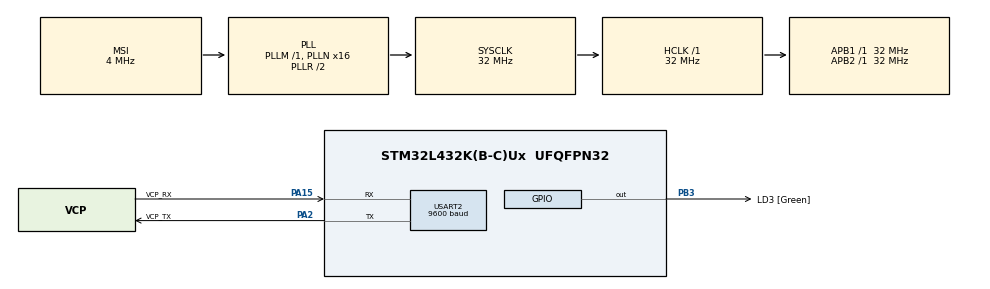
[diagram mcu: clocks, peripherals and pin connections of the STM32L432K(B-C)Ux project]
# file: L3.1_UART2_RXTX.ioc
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Dma.Request0=USART2_RX
Dma.Request1=USART2_TX
Dma.USART2_RX.0.Direction=DMA_PERIPH_TO_MEMORY
Dma.USART2_RX.0.Instance=DMA1_Channel6
Dma.USART2_RX.0.MemDataAlignment=DMA_MDATAALIGN_BYTE
Dma.USART2_RX.0.MemInc=DMA_MINC_ENABLE
Dma.USART2_RX.0.Mode=DMA_NORMAL
Dma.USART2_RX.0.PeriphDataAlignment=DMA_PDATAALIGN_BYTE
Dma.USART2_RX.0.PeriphInc=DMA_PINC_DISABLE
Dma.USART2_RX.0.Priority=DMA_PRIORITY_LOW
Dma.USART2_TX.1.Direction=DMA_MEMORY_TO_PERIPH
Dma.USART2_TX.1.Instance=DMA1_Channel7
Dma.USART2_TX.1.MemDataAlignment=DMA_MDATAALIGN_BYTE
Dma.USART2_TX.1.MemInc=DMA_MINC_ENABLE
Dma.USART2_TX.1.Mode=DMA_NORMAL
Dma.USART2_TX.1.PeriphDataAlignment=DMA_PDATAALIGN_BYTE
Dma.USART2_TX.1.PeriphInc=DMA_PINC_DISABLE
Dma.USART2_TX.1.Priority=DMA_PRIORITY_LOW
Mcu.Family=STM32L4
Mcu.Name=STM32L432K(B-C)Ux
Mcu.Package=UFQFPN32
NVIC.DMA1_Channel6_IRQn=true\:0\:0\:false\:false\:true\:false\:true\:true
NVIC.DMA1_Channel7_IRQn=true\:0\:0\:false\:false\:true\:false\:true\:true
NVIC.PriorityGroup=NVIC_PRIORITYGROUP_4
NVIC.USART2_IRQn=true\:0\:0\:false\:false\:true\:true\:true\:true
PA0.GPIO_Label=MCO [High speed clock in]
PA0.Mode=HSE-External-Clock-Source-for-LittleOrca
PA0.Signal=RCC_CK_IN
PA13\ (JTMS-SWDIO).GPIO_Label=SWDIO
PA13\ (JTMS-SWDIO).Mode=Serial_Wire
PA13\ (JTMS-SWDIO).Signal=SYS_JTMS-SWDIO
PA14\ (JTCK-SWCLK).GPIO_Label=SWCLK
PA14\ (JTCK-SWCLK).Mode=Serial_Wire
PA14\ (JTCK-SWCLK).Signal=SYS_JTCK-SWCLK
PA15\ (JTDI).GPIO_Label=VCP_RX
PA15\ (JTDI).Mode=Asynchronous
PA15\ (JTDI).Signal=USART2_RX
PA2.GPIO_Label=VCP_TX
PA2.Mode=Asynchronous
PA2.Signal=USART2_TX
PB3\ (JTDO-TRACESWO).GPIO_Label=LD3 [Green]
PB3\ (JTDO-TRACESWO).Signal=GPIO_Output
PC14-OSC32_IN\ (PC14).Mode=LSE-External-Oscillator
PC14-OSC32_IN\ (PC14).Signal=RCC_OSC32_IN
PC15-OSC32_OUT\ (PC15).Mode=LSE-External-Oscillator
PC15-OSC32_OUT\ (PC15).Signal=RCC_OSC32_OUT
ProjectManager.HeapSize=0x200
ProjectManager.StackSize=0x400
ProjectManager.TargetToolchain=STM32CubeIDE
RCC.AHBFreq_Value=32000000
RCC.APB1Freq_Value=32000000
RCC.APB1TimFreq_Value=32000000
RCC.APB2Freq_Value=32000000
RCC.APB2TimFreq_Value=32000000
RCC.CortexFreq_Value=32000000
RCC.HCLKFreq_Value=32000000
RCC.HSE_VALUE=8000000
RCC.HSI16_VALUE=16000000
RCC.HSI48_VALUE=48000000
RCC.HSI_VALUE=16000000
RCC.MSI_VALUE=4000000
RCC.PLLMUL=RCC_PLLMUL_4
RCC.PLLN=16
RCC.SYSCLKFreq_VALUE=32000000
RCC.SYSCLKSource=RCC_SYSCLKSOURCE_PLLCLK
RCC.VCOOutputFreq_Value=64000000
USART2.BaudRate=9600
USART2.VirtualMode-Asynchronous=VM_ASYNC
board=NUCLEO-L432KC

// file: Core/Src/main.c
/* USER CODE BEGIN Header */
/**
  ******************************************************************************
  * @file           : main.c
  * @brief          : Main program body
  ******************************************************************************
  * @attention
  *
  * Copyright (c) 2024 STMicroelectronics.
  * All rights reserved.
  *
  * This software is licensed under terms that can be found in the LICENSE file
  * in the root directory of this software component.
  * If no LICENSE file comes with this software, it is provided AS-IS.
  *
  ******************************************************************************
  */

/*
 * ChatGPT:	- HAL_UART_ErrorCallback vs HAL_DMA_ErrorCallback
 *			- stm32 L4 HAL_UART_ErrorCallback error handling logic
 *
 *
 * Structure of HAL_DMA_ErrorCallback
 *
 * Identify the DMA Instance:
 * 		Use the hdma parameter to determine which DMA channel experienced the error.
 *
 * Log the Error:
 * 		Use a logging mechanism (e.g., printing to console, sending an error message,
 * 		etc.) to capture the error context.
 *
 * Clear the Error:
 * 		If applicable, you might want to clear the error flags associated with the DMA.
 *
 * Abort the DMA Transfer:
 * 		Call HAL_DMA_Abort() to stop the DMA transfer and clean up any resources.
 *
 * Optionally, Reinitialize the DMA:
 * 		Depending on the application, you might need to reconfigure or restart the DMA
 * 		after handling the error.
 *
 * Notify Other System Components:
 * 		If other parts of your system need to be aware of the error (e.g., an application layer),
 * 		send a notification or update a status variable.
 */

/*
 * Breakdown of Key Components
 *
 * Error Callback Function:
 * 		This function is called automatically when a UART error occurs. Ensure it's configured
 * 		properly in your UART initialization.
 *
 * dentify UART Instance:
 * 		The code checks if the error relates to UART2. This is crucial for applications with multiple UARTs.
 *
 * DMA Abort Handling:
 * 		Abort the DMA: Call HAL_DMA_Abort() to stop the ongoing DMA transfer. Check the return value
 * 		to ensure the abort was successful.
 *
 * 		Clear Error Flags: Use __HAL_DMA_CLEAR_FLAG() to clear relevant error flags, such as transfer
 * 		errors, FIFO errors, and direct memory errors.
 *
 * Stop UART DMA:
 * 		Use HAL_UART_DMAStop() to stop any ongoing DMA operations related to the UART. This prevents
 * 		further erroneous transmissions.
 *
 * Optional Reinitialization:
 * 		If necessary, you can reinitialize the UART peripheral by uncommenting the HAL_UART_Init() line.
 * 		This step may be required depending on your application's state management.
 *
 * Notify Other Components:
 * 		Consider implementing a mechanism to notify other parts of your application about the error, such
 * 		as setting an error state or invoking an error handler function.
 */

/* USER CODE END Header */
#include "main.h"

/* USER CODE BEGIN Includes */
#include "stdio.h"
#include "string.h"
/* USER CODE END Includes */

UART_HandleTypeDef huart2;
DMA_HandleTypeDef hdma_usart2_rx;
DMA_HandleTypeDef hdma_usart2_tx;

/* USER CODE BEGIN PV */
uint8_t dataBufferTx[] = "Hello, UART with DMA!\r\n";		//data buffer tx
/* USER CODE END PV */

void SystemClock_Config(void);
static void MX_GPIO_Init(void);
static void MX_DMA_Init(void);
static void MX_USART2_UART_Init(void);

/* USER CODE BEGIN 0 */

/*
 * Error Code description UART1
 * 0xA0....UART1 Unknown Error
 * 0xA1....UART1 Overrun Error
 * 0xA2....UART1 Noise Error
 * 0xA3....UART1 Framing Error
 * 0xA4....UART1 Parity Error
 */

/*
 * Error Code description UART2
 * 0xB0....UART2 Unknown Error
 * 0xB1....UART2 Overrun Error
 * 0xB2....UART2 Noise Error
 * 0xB3....UART2 Framing Error
 * 0xB4....UART2 Parity Error
 */

void LogError(uint8_t errorCode)
{
	char message[50];

    // Implement your logging mechanism, e.g., send to UART, store in buffer

	// Example: send error code to a debug UART
    sprintf(message, "UART Error: 0x%08X\n", errorCode);
    HAL_UART_Transmit(&huart2, (uint8_t*)message, strlen(message), HAL_MAX_DELAY);
}

void resetUART(UART_HandleTypeDef *huart)
{
	if (huart == NULL || huart->Instance != USART1 || huart->Instance != USART2)
	{
		return; // Error: Invalid handle
	}

	if (huart->Instance == USART1)
		{
			// Disable the UART2 peripheral
			__HAL_UART_DISABLE(huart);

			// Clear the RX buffer
			while (__HAL_UART_GET_FLAG(huart, UART_FLAG_RXNE))
			{
				(void)huart->Instance->RDR; // Read the data register to clear RXNE
			}

			// Reset the UART2 peripheral
			__HAL_RCC_USART1_FORCE_RESET();
			__HAL_RCC_USART1_RELEASE_RESET();

			// Reinitialize the UART2 peripheral
			if (HAL_UART_Init(huart) == HAL_OK)		// Init UART1
			{
				// Reinitialize successful
			}else
			{
				// Reinitialize not successful
			}
		}

	if (huart->Instance == USART2)
	{
		// Disable the UART2 peripheral
		__HAL_UART_DISABLE(huart);

		// Clear the RX buffer
		while (__HAL_UART_GET_FLAG(huart, UART_FLAG_RXNE))
		{
			(void)huart->Instance->RDR; // Read the data register to clear RXNE
		}

		// Reset the UART2 peripheral
		__HAL_RCC_USART2_FORCE_RESET();
		__HAL_RCC_USART2_RELEASE_RESET();

		// Reinitialize the UART2 peripheral
		if (HAL_UART_Init(huart) == HAL_OK)		// Init UART2
		{
			// Reinitialize successful
		}else
		{
			// Reinitialize not successful
		}
	}
}

//void Error_Handler(void)
//{
//	// User can add their own implementation to report the HAL error return state
//    while (1)
//    {
//    	// Optionally toggle an LED or send an error message
//        HAL_Delay(100);
//        // Example: Toggle an LED connected to a GPIO pin
//        HAL_GPIO_TogglePin(LD3_GPIO_Port, LD3_Pin); // Adjust pin according to your setup
//    }
//}

//------------------------------Error Handling Functions UART1 and UART2------------------------------
// Handle overrun error
void HandleOverrunErrorUART(UART_HandleTypeDef *huart)
{
	if (huart->Instance == USART2)		// log the error
	{
		LogError(0xA1);
	}else if (huart->Instance == USART2)
	{
		LogError(0xB1);
	}

	__HAL_UART_CLEAR_OREFLAG(huart);	// clear error flag
	resetUART(huart);					// reset UART
}

// Handle noise error
void HandleNoiseErrorUART(UART_HandleTypeDef *huart)
{
	if (huart->Instance == USART2)		// log the error
	{
		LogError(0xA2);
	}else if (huart->Instance == USART2)
	{
		LogError(0xB2);
	}

	__HAL_UART_CLEAR_NEFLAG(huart);		// clear error flag
}

// Handle framing error
void HandleFramingErrorUART(UART_HandleTypeDef *huart)
{
	if (huart->Instance == USART2)		// log the error
	{
		LogError(0xA3);
	}else if (huart->Instance == USART2)
	{
		LogError(0xB3);
	}

	__HAL_UART_CLEAR_FEFLAG(huart);		// clear error flag
}

// Handle parity error
void HandleParityErrorUART(UART_HandleTypeDef *huart)
{
	if (huart->Instance == USART2)		// log the error
	{
		LogError(0xA4);
	}else if (huart->Instance == USART2)
	{
		LogError(0xB4);
	}

	__HAL_UART_CLEAR_PEFLAG(huart);		// clear error flag
}

// Handle unknown errors
void HandleUnknownErrorUART(UART_HandleTypeDef *huart)
{
	if (huart->Instance == USART2)		// log the error
	{
		LogError(0xA0);
	}else if (huart->Instance == USART2)
	{
		LogError(0xB0);
	}

	//resetUART();						// reset UART2
}

void HAL_UART_ErrorCallback(UART_HandleTypeDef *huart)
{
	if (huart == NULL || huart->Instance != USART1 || huart->Instance != USART2)
	{
		return; // Error: Invalid handle
	}

    //Error Handling UART1 and UART2

	switch (huart->ErrorCode)
	{
		case HAL_UART_ERROR_ORE:
			// Handle overrun error
			HandleOverrunErrorUART(huart);
			break;
		case HAL_UART_ERROR_NE:
			// Handle noise error
			HandleNoiseErrorUART(huart);
			break;
		case HAL_UART_ERROR_FE:
			// Handle framing error
			HandleFramingErrorUART(huart);
			break;
		case HAL_UART_ERROR_PE:
			// Handle parity error
			HandleParityErrorUART(huart);
			break;
		default:
			// Handle unknown errors
			HandleUnknownErrorUART(huart);
			break;
	}
}

// Callback for DMA transmission complete
//void HAL_DMA_ErrorCallback(DMA_HandleTypeDef *hdma)
//{
//    // Step 1: Identify the DMA instance
//    if (hdma->Instance == DMA1_Channel6)		//UART2, TX
//    {
//        // Step 2: Log the error for DMA1_Channel6
//        //printf("Error occurred on DMA1_Channel6.\n");
//
//        // Step 3: Clear any error flags
//        __HAL_DMA_CLEAR_FLAG(hdma, DMA_FLAG_TE6);
//    }
//    else if (hdma->Instance == DMA1_Channel7)	//UART2, RX
//    {
//        // Step 2: Log the error for DMA1_Channel7
//    	//printf("Error occurred on DMA1_Channel7.\n");
//
//        // Step 3: Clear any error flags
//        __HAL_DMA_CLEAR_FLAG(hdma, DMA_FLAG_TE7);
//    }
//    // Add additional channels as needed
//
//    // Step 4: Abort the DMA transfer
//    if (HAL_DMA_Abort(hdma) != HAL_OK)
//    {
//        // Handle abort error if necessary
//    	//printf("Failed to abort DMA transfer.\n");
//    }
//
//    // Step 5: Optional - Reinitialize the DMA if needed
//    // HAL_DMA_Init(hdma); // Uncomment if you wish to reinitialize
//
//    // Step 6: Notify other parts of the application if needed
//    // e.g., set an error flag, send a message, etc.
//}

/* USER CODE END 0 */

int main(void)
{

  /* MCU Configuration--------------------------------------------------------*/

  /* Reset of all peripherals, Initializes the Flash interface and the Systick. */
  HAL_Init();

  /* Configure the system clock */
  SystemClock_Config();

  /* Initialize all configured peripherals */
  MX_GPIO_Init();
  MX_DMA_Init();
  MX_USART2_UART_Init();

  /* Infinite loop */
  /* USER CODE BEGIN WHILE */
  while (1)
  {
	  HAL_Delay(1000);

	  if (HAL_UART_Transmit_DMA(&huart2, dataBufferTx, sizeof(dataBufferTx)) != HAL_OK)
	  {
		  // Transmission error handling
		  Error_Handler();
	  }

    /* USER CODE END WHILE */

  }
}

void SystemClock_Config(void)
{
  RCC_OscInitTypeDef RCC_OscInitStruct = {0};
  RCC_ClkInitTypeDef RCC_ClkInitStruct = {0};

  /** Configure the main internal regulator output voltage
  */
  if (HAL_PWREx_ControlVoltageScaling(PWR_REGULATOR_VOLTAGE_SCALE1) != HAL_OK)
  {
    Error_Handler();
  }

  /** Configure LSE Drive Capability
  */
  HAL_PWR_EnableBkUpAccess();
  __HAL_RCC_LSEDRIVE_CONFIG(RCC_LSEDRIVE_LOW);

  /** Initializes the RCC Oscillators according to the specified parameters
  * in the RCC_OscInitTypeDef structure.
  */
  RCC_OscInitStruct.OscillatorType = RCC_OSCILLATORTYPE_LSE|RCC_OSCILLATORTYPE_MSI;
  RCC_OscInitStruct.LSEState = RCC_LSE_ON;
  RCC_OscInitStruct.MSIState = RCC_MSI_ON;
  RCC_OscInitStruct.MSICalibrationValue = 0;
  RCC_OscInitStruct.MSIClockRange = RCC_MSIRANGE_6;
  RCC_OscInitStruct.PLL.PLLState = RCC_PLL_ON;
  RCC_OscInitStruct.PLL.PLLSource = RCC_PLLSOURCE_MSI;
  RCC_OscInitStruct.PLL.PLLM = 1;
  RCC_OscInitStruct.PLL.PLLN = 16;
  RCC_OscInitStruct.PLL.PLLP = RCC_PLLP_DIV7;
  RCC_OscInitStruct.PLL.PLLQ = RCC_PLLQ_DIV2;
  RCC_OscInitStruct.PLL.PLLR = RCC_PLLR_DIV2;
  if (HAL_RCC_OscConfig(&RCC_OscInitStruct) != HAL_OK)
  {
    Error_Handler();
  }

  /** Initializes the CPU, AHB and APB buses clocks
  */
  RCC_ClkInitStruct.ClockType = RCC_CLOCKTYPE_HCLK|RCC_CLOCKTYPE_SYSCLK
                              |RCC_CLOCKTYPE_PCLK1|RCC_CLOCKTYPE_PCLK2;
  RCC_ClkInitStruct.SYSCLKSource = RCC_SYSCLKSOURCE_PLLCLK;
  RCC_ClkInitStruct.AHBCLKDivider = RCC_SYSCLK_DIV1;
  RCC_ClkInitStruct.APB1CLKDivider = RCC_HCLK_DIV1;
  RCC_ClkInitStruct.APB2CLKDivider = RCC_HCLK_DIV1;

  if (HAL_RCC_ClockConfig(&RCC_ClkInitStruct, FLASH_LATENCY_1) != HAL_OK)
  {
    Error_Handler();
  }

  /** Enable MSI Auto calibration
  */
  HAL_RCCEx_EnableMSIPLLMode();
}

static void MX_USART2_UART_Init(void)
{

  huart2.Instance = USART2;
  huart2.Init.BaudRate = 9600;
  huart2.Init.WordLength = UART_WORDLENGTH_8B;
  huart2.Init.StopBits = UART_STOPBITS_1;
  huart2.Init.Parity = UART_PARITY_NONE;
  huart2.Init.Mode = UART_MODE_TX_RX;
  huart2.Init.HwFlowCtl = UART_HWCONTROL_NONE;
  huart2.Init.OverSampling = UART_OVERSAMPLING_16;
  huart2.Init.OneBitSampling = UART_ONE_BIT_SAMPLE_DISABLE;
  huart2.AdvancedInit.AdvFeatureInit = UART_ADVFEATURE_NO_INIT;
  if (HAL_UART_Init(&huart2) != HAL_OK)
  {
    Error_Handler();
  }

}

static void MX_DMA_Init(void)
{

  /* DMA controller clock enable */
  __HAL_RCC_DMA1_CLK_ENABLE();

  /* DMA interrupt init */
  /* DMA1_Channel6_IRQn interrupt configuration */
  HAL_NVIC_SetPriority(DMA1_Channel6_IRQn, 0, 0);
  HAL_NVIC_EnableIRQ(DMA1_Channel6_IRQn);
  /* DMA1_Channel7_IRQn interrupt configuration */
  HAL_NVIC_SetPriority(DMA1_Channel7_IRQn, 0, 0);
  HAL_NVIC_EnableIRQ(DMA1_Channel7_IRQn);

}

static void MX_GPIO_Init(void)
{
  GPIO_InitTypeDef GPIO_InitStruct = {0};

  /* GPIO Ports Clock Enable */
  __HAL_RCC_GPIOC_CLK_ENABLE();
  __HAL_RCC_GPIOA_CLK_ENABLE();
  __HAL_RCC_GPIOB_CLK_ENABLE();

  /*Configure GPIO pin Output Level */
  HAL_GPIO_WritePin(LD3_GPIO_Port, LD3_Pin, GPIO_PIN_RESET);

  /*Configure GPIO pin : LD3_Pin */
  GPIO_InitStruct.Pin = LD3_Pin;
  GPIO_InitStruct.Mode = GPIO_MODE_OUTPUT_PP;
  GPIO_InitStruct.Pull = GPIO_NOPULL;
  GPIO_InitStruct.Speed = GPIO_SPEED_FREQ_LOW;
  HAL_GPIO_Init(LD3_GPIO_Port, &GPIO_InitStruct);

}

void Error_Handler(void)
{
  __disable_irq();
  while (1)
  {
  }
}
